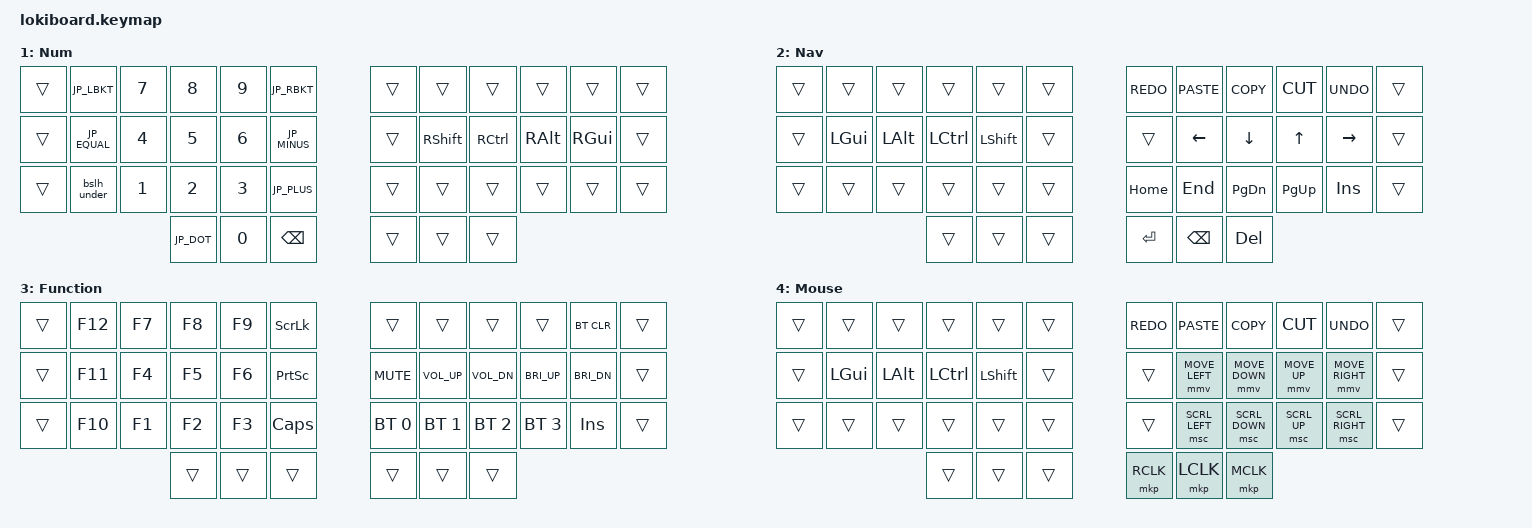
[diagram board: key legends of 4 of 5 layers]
#include <behaviors.dtsi>
#include <dt-bindings/zmk/keys.h>
#include <dt-bindings/zmk/bt.h>
#include <dt-bindings/zmk/pointing.h>
#include "locale/keys_jp.h"

// Layers
#define DEFAULT    0
#define NUM_LAY    1
#define NAV_LAY    2
#define FN_LAY     3
#define MOUSE_LAY  4

// Thumb keys
#define NUM_MOD     &hlt NUM_LAY BSPC
#define NAV_MOD     &hlt NAV_LAY SPACE
#define FN_MOD      &hlt FN_LAY DEL
#define MOUSE_MOD   &hlt MOUSE_LAY TAB

// Home row mods
#define HRML(k1, k2, k3, k4) &ht LGUI k1  &ht LALT k2  &ht LCTRL k3  &ht LSHIFT k4
#define HRMR(k1, k2, k3, k4) &ht RSHIFT k1  &ht RCTRL k2  &ht RALT k3  &ht RGUI k4

/ {
    behaviors {
        lt {
            tapping-term-ms = <220>;
            quick-tap-ms = <150>;
        };

        hlt: hold_tap_layer {
            compatible = "zmk,behavior-hold-tap";
            #binding-cells = <2>;
            flavor = "tap-preferred";
            tapping-term-ms = <220>;
            quick-tap-ms = <150>;
            require-prior-idle-ms = <75>;
            bindings = <&mo>, <&kp>;
        };

        ht: hold_tap {
            compatible = "zmk,behavior-hold-tap";
            #binding-cells = <2>;
            flavor = "tap-preferred";
            tapping-term-ms = <220>;
            quick-tap-ms = <150>;
            require-prior-idle-ms = <75>;
            bindings = <&kp>, <&kp>;
        };

        // ^ (tap) ~ (shift)
        caret_tilde: caret_tilde {
            compatible = "zmk,behavior-mod-morph";
            #binding-cells = <0>;
            bindings = <&kp JP_CARET>, <&kp JP_TILDE>;
            mods = <(MOD_LSFT|MOD_RSFT)>;
        };

        // \ (tap) _ (shift)
        bslh_under: bslh_under {
            compatible = "zmk,behavior-mod-morph";
            #binding-cells = <0>;
            bindings = <&kp JP_BSLH>, <&kp JP_UNDERSCORE>;
            mods = <(MOD_LSFT|MOD_RSFT)>;
        };

        // ¥ (tap) | (shift)
        yen_pipe: yen_pipe {
            compatible = "zmk,behavior-mod-morph";
            #binding-cells = <0>;
            bindings = <&kp JP_YEN>, <&kp JP_PIPE>;
            mods = <(MOD_LSFT|MOD_RSFT)>;
        };

        // @ (tap) ` (shift)
        at_grave: at_grave {
            compatible = "zmk,behavior-mod-morph";
            #binding-cells = <0>;
            bindings = <&kp JP_AT>, <&kp JP_GRAVE>;
            mods = <(MOD_LSFT|MOD_RSFT)>;
        };

        // / (tap) ? (shift)
        fslh_qmark: fslh_qmark {
            compatible = "zmk,behavior-mod-morph";
            #binding-cells = <0>;
            bindings = <&kp JP_FSLH>, <&kp JP_QMARK>;
            mods = <(MOD_LSFT|MOD_RSFT)>;
        };

        // ; (tap) + (shift)  — JP keyboard behaviour for the ; key
        semi_plus: semi_plus {
            compatible = "zmk,behavior-mod-morph";
            #binding-cells = <0>;
            bindings = <&kp JP_SEMICOLON>, <&kp JP_PLUS>;
            mods = <(MOD_LSFT|MOD_RSFT)>;
        };

        // ; key with RGUI hold
        ht_semi: ht_semi {
            compatible = "zmk,behavior-hold-tap";
            #binding-cells = <2>;
            flavor = "tap-preferred";
            tapping-term-ms = <220>;
            quick-tap-ms = <150>;
            require-prior-idle-ms = <75>;
            bindings = <&kp>, <&semi_plus>;
        };
    };

    keymap {
        compatible = "zmk,keymap";

        default_layer {
            display-name = "Main";
            bindings = <
        //╭──────────────┬────────┬────────┬────────┬────────┬────────╮   ╭────────┬────────┬────────┬────────┬────────┬──────────╮
        //│  ^ ~         │  Q     │  W     │  E     │  R     │  T     │   │  Y     │  U     │  I     │  O     │  P     │  @ `     │
            &caret_tilde   &kp Q    &kp W    &kp E    &kp R    &kp T        &kp Y    &kp U    &kp I    &kp O    &kp P    &at_grave
        //├──────────────┼────────┼────────┼────────┼────────┼────────┤   ├────────┼────────┼────────┼────────┼────────┼──────────┤
        //│  \ _         │  A     │  S     │  D     │  F     │  G     │   │  H     │  J     │  K     │  L     │  ; +   │  :       │
            &bslh_under    HRML(A,  S,       D,       F)       &kp G        &kp H    &ht RSHIFT J  &ht RCTRL K  &ht RALT L  &ht_semi RGUI 0  &kp JP_COLON
        //├──────────────┼────────┼────────┼────────┼────────┼────────┤   ├────────┼────────┼────────┼────────┼────────┼──────────┤
        //│  ¥ |         │  Z     │  X     │  C     │  V     │  B     │   │  N     │  M     │  ,     │  .     │  / ?   │  - =     │
            &yen_pipe      &kp Z    &kp X    &kp C    &kp V    &kp B        &kp N    &kp M    &kp JP_COMMA  &kp JP_DOT  &fslh_qmark  &kp JP_MINUS
        //╰──────────────┴────────┴────────┼────────┼────────┼────────┤   ├────────┼────────┼────────┼────────┴────────┴──────────╯
        //                                 │  ESC   │  NAV   │ MOUSE  │   │ ENTER  │  NUM   │  FN    │
                                             &kp ESC  NAV_MOD  MOUSE_MOD    &kp ENTER  NUM_MOD  FN_MOD
        //                                 ╰────────┴────────┴────────╯   ╰────────┴────────┴────────╯
            >;
        };

        num_layer {
            display-name = "Num";
            bindings = <
        //╭────────┬──────────────┬────────┬────────┬────────┬──────────────╮   ╭────────┬────────────┬───────────┬──────────┬──────────┬────────╮
        //│        │  [ {         │  7     │  8     │  9     │  ] }         │   │        │            │           │          │          │        │
            &trans   &kp JP_LBKT   &kp N7   &kp N8   &kp N9   &kp JP_RBKT        &trans   &trans       &trans      &trans     &trans     &trans
        //├────────┼──────────────┼────────┼────────┼────────┼──────────────┤   ├────────┼────────────┼───────────┼──────────┼──────────┼────────┤
        //│        │  = ~         │  4     │  5     │  6     │  -           │   │        │  RSHIFT    │  RCTRL    │  RALT    │  RGUI    │        │
            &trans   &kp JP_EQUAL  &kp N4   &kp N5   &kp N6   &kp JP_MINUS       &trans   &kp RSHIFT   &kp RCTRL   &kp RALT   &kp RGUI   &trans
        //├────────┼──────────────┼────────┼────────┼────────┼──────────────┤   ├────────┼────────────┼───────────┼──────────┼──────────┼────────┤
        //│        │  \ _         │  1     │  2     │  3     │  +           │   │        │            │           │          │          │        │
            &trans   &bslh_under   &kp N1   &kp N2   &kp N3   &kp JP_PLUS        &trans   &trans       &trans      &trans     &trans     &trans
        //╰────────┴──────────────┴────────┼────────┼────────┼──────────────┤   ├────────┼────────────┼───────────┼──────────┴──────────┴────────╯
        //                                 │  .     │  0     │  BSPC        │   │        │            │           │
                                             &kp JP_DOT  &kp N0  &kp BSPC         &trans   &trans       &trans
        //                                 ╰────────┴────────┴──────────────╯   ╰────────┴────────────┴───────────╯
            >;
        };

        nav_layer {
            display-name = "Nav";
            bindings = <
        //╭────────┬────────┬────────┬────────┬────────┬────────╮   ╭────────────┬─────────────┬────────────┬───────────┬────────────┬────────╮
        //│        │        │        │        │        │        │   │  REDO      │  PASTE      │  COPY      │  CUT      │  UNDO      │        │
            &trans   &trans   &trans   &trans   &trans   &trans       &kp K_REDO   &kp K_PASTE   &kp K_COPY   &kp K_CUT   &kp K_UNDO   &trans
        //├────────┼────────┼────────┼────────┼────────┼────────┤   ├────────────┼─────────────┼────────────┼───────────┼────────────┼────────┤
        //│        │  LGUI  │  LALT  │ LCTRL  │ LSHIFT │        │   │            │  LEFT       │  DOWN      │  UP       │  RIGHT     │        │
            &trans   &kp LGUI  &kp LALT  &kp LCTRL  &kp LSHIFT  &trans  &trans   &kp LEFT      &kp DOWN     &kp UP      &kp RIGHT    &trans
        //├────────┼────────┼────────┼────────┼────────┼────────┤   ├────────────┼─────────────┼────────────┼───────────┼────────────┼────────┤
        //│        │        │        │        │        │        │   │  HOME      │  END        │  PAGE DN   │  PAGE UP  │  INSERT    │        │
            &trans   &trans   &trans   &trans   &trans   &trans       &kp HOME     &kp END       &kp PG_DN    &kp PG_UP   &kp INS      &trans
        //╰────────┴────────┴────────┼────────┼────────┼────────┤   ├────────────┼─────────────┼────────────┼───────────┴────────────┴────────╯
        //                           │        │        │        │   │  ENTER     │  BKSP       │  DEL       │
                                       &trans   &trans   &trans       &kp ENTER    &kp BKSP      &kp DEL
        //                           ╰────────┴────────┴────────╯   ╰────────────┴─────────────┴────────────╯
            >;
        };

        fn_layer {
            display-name = "Function";
            bindings = <
        //╭────────┬─────────┬────────┬────────┬────────┬────────────╮   ╭──────────────┬─────────────┬─────────────┬──────────────┬─────────────┬────────╮
        //│        │  F12    │  F7    │  F8    │  F9    │ SCROLL LCK │   │              │             │             │              │  BT CLEAR   │        │
            &trans   &kp F12   &kp F7   &kp F8   &kp F9   &kp SLCK         &trans         &trans        &trans        &trans         &bt BT_CLR    &trans
        //├────────┼─────────┼────────┼────────┼────────┼────────────┤   ├──────────────┼─────────────┼─────────────┼──────────────┼─────────────┼────────┤
        //│        │  F11    │  F4    │  F5    │  F6    │ PRINT SCR  │   │  MUTE        │  VOL UP     │  VOL DN     │  INC BRIGHT  │  DEC BRIGHT │        │
            &trans   &kp F11   &kp F4   &kp F5   &kp F6   &kp PSCRN        &kp K_MUTE    &kp K_VOL_UP  &kp K_VOL_DN  &kp C_BRI_UP  &kp C_BRI_DN  &trans
        //├────────┼─────────┼────────┼────────┼────────┼────────────┤   ├──────────────┼─────────────┼─────────────┼──────────────┼─────────────┼────────┤
        //│        │  F10    │  F1    │  F2    │  F3    │  CAPS LCK  │   │  PROFILE 0   │  PROFILE 1  │  PROFILE 2  │  PROFILE 3   │  INSERT     │        │
            &trans   &kp F10   &kp F1   &kp F2   &kp F3   &kp CAPS         &bt BT_SEL 0   &bt BT_SEL 1  &bt BT_SEL 2  &bt BT_SEL 3   &kp INS      &trans
        //╰────────┴─────────┴────────┼────────┼────────┼────────────┤   ├──────────────┼─────────────┼─────────────┼──────────────┴─────────────┴────────╯
        //                            │        │        │            │   │              │             │             │
                                        &trans   &trans   &trans           &trans         &trans        &trans
        //                            ╰────────┴────────┴────────────╯   ╰──────────────┴─────────────┴─────────────╯
            >;
        };

        mouse_layer {
            display-name = "Mouse";
            bindings = <
        //╭────────┬────────┬────────┬────────┬────────┬────────╮   ╭────────────────┬────────────────┬────────────────┬──────────────┬─────────────────┬────────╮
        //│        │        │        │        │        │        │   │  REDO          │  PASTE         │  COPY          │  CUT         │  UNDO           │        │
            &trans   &trans   &trans   &trans   &trans   &trans        &kp K_REDO       &kp K_PASTE      &kp K_COPY       &kp K_CUT      &kp K_UNDO        &trans
        //├────────┼────────┼────────┼────────┼────────┼────────┤   ├────────────────┼────────────────┼────────────────┼──────────────┼─────────────────┼────────┤
        //│        │  LGUI  │  LALT  │ LCTRL  │ LSHIFT │        │   │                │  MOVE LEFT     │  MOVE DOWN     │  MOVE UP     │  MOVE RIGHT     │        │
            &trans   &kp LGUI  &kp LALT  &kp LCTRL  &kp LSHIFT  &trans  &trans        &mmv MOVE_LEFT   &mmv MOVE_DOWN   &mmv MOVE_UP   &mmv MOVE_RIGHT   &trans
        //├────────┼────────┼────────┼────────┼────────┼────────┤   ├────────────────┼────────────────┼────────────────┼──────────────┼─────────────────┼────────┤
        //│        │        │        │        │        │        │   │                │  SCROLL LEFT   │  SCROLL DOWN   │  SCROLL UP   │  SCROLL RIGHT   │        │
            &trans   &trans   &trans   &trans   &trans   &trans        &trans           &msc SCRL_LEFT   &msc SCRL_DOWN   &msc SCRL_UP   &msc SCRL_RIGHT   &trans
        //╰────────┴────────┴────────┼────────┼────────┼────────┤   ├────────────────┼────────────────┼────────────────┼──────────────┴─────────────────┴────────╯
        //                           │        │        │        │   │  RIGHT CLICK   │  LEFT CLICK    │  MID CLICK     │
                                       &trans   &trans   &trans        &mkp RCLK        &mkp LCLK        &mkp MCLK
        //                           ╰────────┴────────┴────────╯   ╰────────────────┴────────────────┴────────────────╯
            >;
        };
    };
};
